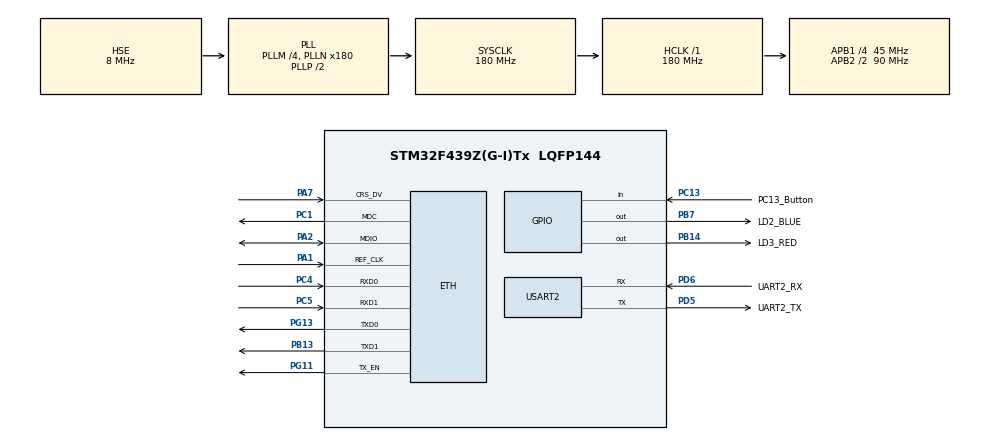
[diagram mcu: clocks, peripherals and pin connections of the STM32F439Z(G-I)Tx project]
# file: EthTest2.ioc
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Dma.MEMTOMEM.0.Direction=DMA_MEMORY_TO_MEMORY
Dma.MEMTOMEM.0.FIFOMode=DMA_FIFOMODE_ENABLE
Dma.MEMTOMEM.0.FIFOThreshold=DMA_FIFO_THRESHOLD_FULL
Dma.MEMTOMEM.0.Instance=DMA2_Stream0
Dma.MEMTOMEM.0.MemBurst=DMA_MBURST_SINGLE
Dma.MEMTOMEM.0.MemDataAlignment=DMA_MDATAALIGN_BYTE
Dma.MEMTOMEM.0.MemInc=DMA_MINC_ENABLE
Dma.MEMTOMEM.0.Mode=DMA_NORMAL
Dma.MEMTOMEM.0.PeriphBurst=DMA_PBURST_SINGLE
Dma.MEMTOMEM.0.PeriphDataAlignment=DMA_PDATAALIGN_BYTE
Dma.MEMTOMEM.0.PeriphInc=DMA_PINC_ENABLE
Dma.MEMTOMEM.0.Priority=DMA_PRIORITY_LOW
Dma.Request0=MEMTOMEM
ETH.MACAddr=00\:80\:E1\:00\:00\:02
ETH.MediaInterface=ETH_MEDIA_INTERFACE_RMII
ETH.PhyAddress=0
ETH.RxMode=ETH_RXPOLLING_MODE
LWIP.DHCP_DEBUG=LWIP_DBG_ON
LWIP.ETHARP_DEBUG=LWIP_DBG_ON
LWIP.ICMP_DEBUG=LWIP_DBG_ON
LWIP.LWIP_DHCP_CHECK_LINK_UP=1
LWIP.NETIF_DEBUG=LWIP_DBG_ON
LWIP.PBUF_DEBUG=LWIP_DBG_ON
LWIP.SYS_DEBUG=LWIP_DBG_ON
LWIP.UDP_DEBUG=LWIP_DBG_ON
LWIP.Version=v2.0.3_Cube
Mcu.Family=STM32F4
Mcu.Name=STM32F439Z(G-I)Tx
Mcu.Package=LQFP144
NVIC.ETH_IRQn=true\:0\:0\:false\:false\:true\:true
NVIC.PriorityGroup=NVIC_PRIORITYGROUP_4
NVIC.USART2_IRQn=true\:0\:0\:false\:false\:true\:true
PA1.Mode=RMII
PA1.Signal=ETH_REF_CLK
PA13.Mode=Serial_Wire
PA13.Signal=SYS_JTMS-SWDIO
PA14.Mode=Serial_Wire
PA14.Signal=SYS_JTCK-SWCLK
PA2.Mode=RMII
PA2.Signal=ETH_MDIO
PA7.Mode=RMII
PA7.Signal=ETH_CRS_DV
PB13.Mode=RMII
PB13.Signal=ETH_TXD1
PB14.GPIO_Label=LD3_RED
PB14.Signal=GPIO_Output
PB7.GPIO_Label=LD2_BLUE
PB7.Signal=GPIO_Output
PC1.Mode=RMII
PC1.Signal=ETH_MDC
PC13.GPIO_Label=PC13_Button
PC13.Signal=GPIO_Input
PC4.Mode=RMII
PC4.Signal=ETH_RXD0
PC5.Mode=RMII
PC5.Signal=ETH_RXD1
PD5.GPIO_Label=UART2_TX
PD5.Mode=Asynchronous
PD5.Signal=USART2_TX
PD6.GPIO_Label=UART2_RX
PD6.Mode=Asynchronous
PD6.Signal=USART2_RX
PG11.Mode=RMII
PG11.Signal=ETH_TX_EN
PG13.Mode=RMII
PG13.Signal=ETH_TXD0
PH0/OSC_IN.Mode=HSE-External-Oscillator
PH0/OSC_IN.Signal=RCC_OSC_IN
PH1/OSC_OUT.Mode=HSE-External-Oscillator
PH1/OSC_OUT.Signal=RCC_OSC_OUT
ProjectManager.HeapSize=0x200
ProjectManager.StackSize=0x400
ProjectManager.TargetToolchain=SW4STM32
RCC.48MHZClocksFreq_Value=90000000
RCC.AHBFreq_Value=180000000
RCC.APB1CLKDivider=RCC_HCLK_DIV4
RCC.APB1Freq_Value=45000000
RCC.APB1TimFreq_Value=90000000
RCC.APB2CLKDivider=RCC_HCLK_DIV2
RCC.APB2Freq_Value=90000000
RCC.APB2TimFreq_Value=180000000
RCC.CortexFreq_Value=180000000
RCC.HCLKFreq_Value=180000000
RCC.HSE_VALUE=8000000
RCC.HSI_VALUE=16000000
RCC.LSE_VALUE=32768
RCC.PLLM=4
RCC.PLLN=180
RCC.PLLSourceVirtual=RCC_PLLSOURCE_HSE
RCC.SYSCLKFreq_VALUE=180000000
RCC.SYSCLKSource=RCC_SYSCLKSOURCE_PLLCLK
RCC.VCOOutputFreq_Value=360000000
USART2.VirtualMode=VM_ASYNC
VP_LWIP_VS_Enabled.Mode=Enabled
board=custom

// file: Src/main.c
/* USER CODE BEGIN Header */
/**
  ******************************************************************************
  * @file           : main.c
  * @brief          : Main program body
  ******************************************************************************
  ** This notice applies to any and all portions of this file
  * that are not between comment pairs USER CODE BEGIN and
  * USER CODE END. Other portions of this file, whether
  * inserted by the user or by software development tools
  * are owned by their respective copyright owners.
  *
  * COPYRIGHT(c) 2018 STMicroelectronics
  *
  * Redistribution and use in source and binary forms, with or without modification,
  * are permitted provided that the following conditions are met:
  *   1. Redistributions of source code must retain the above copyright notice,
  *      this list of conditions and the following disclaimer.
  *   2. Redistributions in binary form must reproduce the above copyright notice,
  *      this list of conditions and the following disclaimer in the documentation
  *      and/or other materials provided with the distribution.
  *   3. Neither the name of STMicroelectronics nor the names of its contributors
  *      may be used to endorse or promote products derived from this software
  *      without specific prior written permission.
  *
  * THIS SOFTWARE IS PROVIDED BY THE COPYRIGHT HOLDERS AND CONTRIBUTORS "AS IS"
  * AND ANY EXPRESS OR IMPLIED WARRANTIES, INCLUDING, BUT NOT LIMITED TO, THE
  * IMPLIED WARRANTIES OF MERCHANTABILITY AND FITNESS FOR A PARTICULAR PURPOSE ARE
  * DISCLAIMED. IN NO EVENT SHALL THE COPYRIGHT HOLDER OR CONTRIBUTORS BE LIABLE
  * FOR ANY DIRECT, INDIRECT, INCIDENTAL, SPECIAL, EXEMPLARY, OR CONSEQUENTIAL
  * DAMAGES (INCLUDING, BUT NOT LIMITED TO, PROCUREMENT OF SUBSTITUTE GOODS OR
  * SERVICES; LOSS OF USE, DATA, OR PROFITS; OR BUSINESS INTERRUPTION) HOWEVER
  * CAUSED AND ON ANY THEORY OF LIABILITY, WHETHER IN CONTRACT, STRICT LIABILITY,
  * OR TORT (INCLUDING NEGLIGENCE OR OTHERWISE) ARISING IN ANY WAY OUT OF THE USE
  * OF THIS SOFTWARE, EVEN IF ADVISED OF THE POSSIBILITY OF SUCH DAMAGE.
  *
  ******************************************************************************
  */
/* USER CODE END Header */

#include "main.h"
#include "dma.h"
#include "lwip.h"
#include "usart.h"
#include "gpio.h"

void SystemClock_Config(void);

int main(void)
{

  /* MCU Configuration--------------------------------------------------------*/

  /* Reset of all peripherals, Initializes the Flash interface and the Systick. */
  HAL_Init();

  /* Configure the system clock */
  SystemClock_Config();

  /* Initialize all configured peripherals */
  MX_GPIO_Init();
  MX_DMA_Init();
  MX_USART2_UART_Init();
  MX_LWIP_Init();
  /* USER CODE BEGIN 2 */
  // print out startup message on UART2
  printf("Starting main loop..\r\n");
  HAL_GPIO_TogglePin(LD3_RED_GPIO_Port, LD3_RED_Pin );
  /* USER CODE END 2 */

  /* Infinite loop */
  /* USER CODE BEGIN WHILE */

  uint32_t lpcnt = 0;

  while (1)
  {
	MX_LWIP_Process(); // poll for ethernet rx and timer operations.
	if ( lpcnt == 100000 ) {
		lpcnt = 0;
		HAL_GPIO_TogglePin(LD3_RED_GPIO_Port, LD3_RED_Pin );
	} else {
		lpcnt++;
	}
    /* USER CODE END WHILE */

  }
}

void SystemClock_Config(void)
{
  RCC_OscInitTypeDef RCC_OscInitStruct = {0};
  RCC_ClkInitTypeDef RCC_ClkInitStruct = {0};

  /**Configure the main internal regulator output voltage
  */
  __HAL_RCC_PWR_CLK_ENABLE();
  __HAL_PWR_VOLTAGESCALING_CONFIG(PWR_REGULATOR_VOLTAGE_SCALE1);
  /**Initializes the CPU, AHB and APB busses clocks
  */
  RCC_OscInitStruct.OscillatorType = RCC_OSCILLATORTYPE_HSE;
  RCC_OscInitStruct.HSEState = RCC_HSE_ON;
  RCC_OscInitStruct.PLL.PLLState = RCC_PLL_ON;
  RCC_OscInitStruct.PLL.PLLSource = RCC_PLLSOURCE_HSE;
  RCC_OscInitStruct.PLL.PLLM = 4;
  RCC_OscInitStruct.PLL.PLLN = 180;
  RCC_OscInitStruct.PLL.PLLP = RCC_PLLP_DIV2;
  RCC_OscInitStruct.PLL.PLLQ = 4;
  if (HAL_RCC_OscConfig(&RCC_OscInitStruct) != HAL_OK)
  {
    Error_Handler();
  }
  /**Activate the Over-Drive mode
  */
  if (HAL_PWREx_EnableOverDrive() != HAL_OK)
  {
    Error_Handler();
  }
  /**Initializes the CPU, AHB and APB busses clocks
  */
  RCC_ClkInitStruct.ClockType = RCC_CLOCKTYPE_HCLK|RCC_CLOCKTYPE_SYSCLK
                              |RCC_CLOCKTYPE_PCLK1|RCC_CLOCKTYPE_PCLK2;
  RCC_ClkInitStruct.SYSCLKSource = RCC_SYSCLKSOURCE_PLLCLK;
  RCC_ClkInitStruct.AHBCLKDivider = RCC_SYSCLK_DIV1;
  RCC_ClkInitStruct.APB1CLKDivider = RCC_HCLK_DIV4;
  RCC_ClkInitStruct.APB2CLKDivider = RCC_HCLK_DIV2;

  if (HAL_RCC_ClockConfig(&RCC_ClkInitStruct, FLASH_LATENCY_5) != HAL_OK)
  {
    Error_Handler();
  }
}

void Error_Handler(void)
{
  /* USER CODE BEGIN Error_Handler_Debug */
  /* User can add his own implementation to report the HAL error return state */
  printf("Error Handler Triggered..\r\n");
  /* USER CODE END Error_Handler_Debug */
}

/************************ (C) COPYRIGHT STMicroelectronics *****END OF FILE****/
